# USB3SS0 register map
Vendor: Texas Instruments
Peripheral module from a debugger description file (folder am65x).
Registers are 32-bit, access not given, reset values left out (the file's numbers can be read two ways) unless marked. A register's access mark holds for its fields unless they carry their own. Offsets are as the file gives them; lines under a group give offsets from that group; [hi:lo] are bit positions; {n}, {i} and the like mark numbered series; 'fields as' and 'values as' point back to an identical list; <NAME> marks a mode.

## USB3SS0
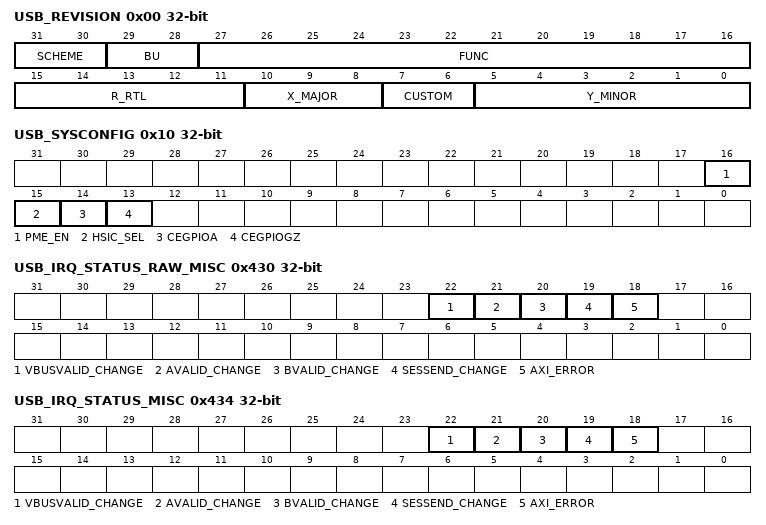
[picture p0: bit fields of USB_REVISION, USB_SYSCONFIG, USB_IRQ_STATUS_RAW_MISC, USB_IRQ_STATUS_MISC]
0x00 USB_REVISION ro — IP Revision Identifier (X.Y.R) Used by software to track features, bugs, and compatibility
  [31:30] SCHEME
  [29:28] BU
  [27:16] FUNC — Module ID
  [15:11] R_RTL — RTL version
  [10:8] X_MAJOR — Major version
  [7:6] CUSTOM — Custom version
  [5:0] Y_MINOR — Minor version
0x10 USB_SYSCONFIG access per field — Controls various parameters of the master and slave interfaces.
  [16] PME_EN rw — Enable signal for the pme_generation. When the Run/Stop bit of the USB Command Register is cleared during USB suspend mode, the core cannot generate event and cannot assert regular interrupt. In this case, the core asserts pme_generation signal to report any wakeup condition if PME_EN is high.
  [15] HSIC_SEL rw — Select USB2PHY when 0, HSIC when 1
  [14] CEGPIOA rw — GPO mode data for CE.
  [13] CEGPIOGZ rw — CE GPO output buffer control.
0x20 USB_IRQ_STATUS_RAW_MAIN_i — The IRQ_STATUS_RAW_MAIN_i register allows the usbss interrupt sources to be manually set when writing a 1 to a specific bit. Parameter i ranges from 0 to 15. Offset = 20h + (i * 10h), where: i = 0h to Fh
  [0] IRQ_STATUS_RAW_MAIN — Write 0: No action Write 1: Set event Read 0: No event pending Read 1: Event pending (access RW1S)
0x24 USB_IRQ_STATUS_MAIN_i — The IRQ_STATUS_MAIN_i register allows the usbss interrupt sources to be manually cleared when writing a 1 to a specific bit. Parameter i ranges from 0 to 15. Offset = 24h + (i * 10h), where: i = 0h to Fh
  [0] IRQ_STATUS_MAIN — Write 0: No action Write 1: Clear event Read 0: No event pending Read 1: Event pending (access RW1C)
0x42C USB_IRQ_EOI_MISC — The End of Interrupt (EOI) MISC Register allows the CPU to acknowledge completion of an interrupt by writing to the EOI for MISC interrupt sources. An eoi_write signal will be generated and another interrupt will be triggered if interrupt sources remain. This register will be reset one cycle after it has been written to. The EOI register is used to re-trigger the pulse interrupt signal to ensure that any nested interrupt events are serviced. The software interrupt handler must write to the EOI register at the end of the current interrupt processing routine, so that new events can re-trigger the pulse interrupt signal again. For level interrupt signals the EOI register is not functional and must not be used.
  [0] EOI_MISC — Write 1 to flag End Of Interrupt 'MISC' (access RW1S)
0x430 USB_IRQ_STATUS_RAW_MISC — The register allows the usbss interrupt sources to be manually set when writing a 1 to a specific bit. Write 0: No action Write 1: Set event Read 0: No event pending Read 1: Event pending
  [22] VBUSVALID_CHANGE — Set when VBUSVALID changes state (access RW1S)
  [21] AVALID_CHANGE — Set when AVALID changes state (access RW1S)
  [20] BVALID_CHANGE — Set when BVALID changes state (access RW1S)
  [19] SESSEND_CHANGE — Set when SESSEND changes state (access RW1S)
  [18] AXI_ERROR — Set by host_system_err when HW detects an error response to AXI master. USB_USBCMD[3] HSEE must be set in the controller. Error reflected in the controller USB_USBSTS[2] HSE field. (access RW1S)
0x434 USB_IRQ_STATUS_MISC — The register allows the usbss interrupt sources to be manually cleared when writing a 1 to a specific bit. Write 0: No action Write 1: Clear event Read 0: No event pending Read 1: Event pending
  [22] VBUSVALID_CHANGE — Set when VBUSVALID changes state (access RW1C)
  [21] AVALID_CHANGE — Set when AVALID changes state (access RW1C)
  [20] BVALID_CHANGE — Set when BVALID changes state (access RW1C)
  [19] SESSEND_CHANGE — Set when SESSEND changes state (access RW1C)
  [18] AXI_ERROR — Set by host_system_err when HW detects an error response to AXI master. USB_USBCMD[3] HSEE must be set in the controller. Error reflected in the controller USB_USBSTS[2] HSE field. (access RW1C)
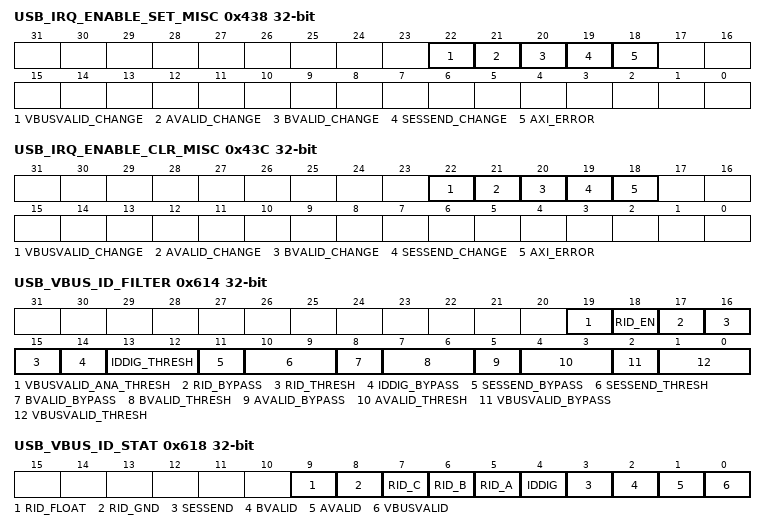
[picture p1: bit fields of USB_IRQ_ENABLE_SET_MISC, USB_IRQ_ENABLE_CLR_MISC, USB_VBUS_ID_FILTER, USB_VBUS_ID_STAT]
0x438 USB_IRQ_ENABLE_SET_MISC — The register allows the usbss interrupt sources to be manually enabled when writing a 1 to a specific bit. Write 0: No action Write 1: Enable event Read 0: Event is disabled Read 1: Event is enabled
  [22] VBUSVALID_CHANGE — Event enable set (access RW1S)
  [21] AVALID_CHANGE — Event enable set (access RW1S)
  [20] BVALID_CHANGE — Event enable set (access RW1S)
  [19] SESSEND_CHANGE — Event enable set (access RW1S)
  [18] AXI_ERROR — Event enable set (access RW1S)
0x43C USB_IRQ_ENABLE_CLR_MISC — The register allows the usbss interrupt sources to be manually disabled when writing a 1 to a specific bit. Write 0: No action Write 1: Disable event Read 0: Event is disabled Read 1: Event is enabled
  [22] VBUSVALID_CHANGE — Event enable clear (access RW1C)
  [21] AVALID_CHANGE — Event enable clear (access RW1C)
  [20] BVALID_CHANGE — Event enable clear (access RW1C)
  [19] SESSEND_CHANGE — Event enable clear (access RW1C)
  [18] AXI_ERROR — Event enable clear (access RW1C)
0x450 USB_IRQ_STATUS_RAW_OTG — The Register allows the OTG interrupt source to be manually triggered when writing a 1 to a specific bit. A read of this register returns the interrupt event pending value. General actions per bit: Write 0: No action Write 1: Set event Read 0: No event pending Read 1: Event pending
  [0] OTG_EVNT — Interrupt raw status for OTG event (access RW1S)
0x454 USB_IRQ_STATUS_OTG — The Register allows the OTG source to be manually cleared when writing a 1 to a specific bit. A read of this register returns the interrupt event pending value. General actions per bit: Write 0: No action Write 1: Clear event Read 0: No event pending Read 1: Event pending
  [0] OTG_EVNT — Interrupt status for OTG event (access RW1C)
0x460 USB_IRQ_STATUS_RAW_ADP — The Register allows the ADP interrupt source to be manually triggered when writing a 1 to a specific bit. A read of this register returns the interrupt event pending value. General actions per bit: Write 0: No action Write 1: Set event Read 0: No event pending Read 1: Event pending
  [0] ADP_EVNT — Interrupt raw status for ADP event (access RW1S)
0x464 USB_IRQ_STATUS_ADP — The Register allows the ADP source to be manually cleared when writing a 1 to a specific bit. A read of this register returns the interrupt event pending value. General actions per bit: Write 0: No action Write 1: Clear event Read 0: No event pending Read 1: Event pending
  [0] ADP_EVNT — Interrupt status for ADP event (access RW1C)
0x470 USB_IRQ_STATUS_RAW_BC — The Register allows the BC interrupt source to be manually triggered when writing a 1 to a specific bit. A read of this register returns the interrupt event pending value. General actions per bit: Write 0: No action Write 1: Set event Read 0: No event pending Read 1: Event pending
  [0] BC_EVNT — Interrupt raw status for BC event (access RW1S)
0x474 USB_IRQ_STATUS_BC — The Register allows the BC source to be manually cleared when writing a 1 to a specific bit. A read of this register returns the interrupt event pending value. General actions per bit: Write 0: No action Write 1: Clear event Read 0: No event pending Read 1: Event pending
  [0] BC_EVNT — Interrupt status for BC event (access RW1C)
0x480 USB_IRQ_STATUS_RAW_PME_GEN — The Register allows the PME_GEN interrupt source to be manually triggered when writing a 1 to a specific bit. A read of this register returns the interrupt event pending value. General actions per bit: Write 0: No action Write 1: Set event Read 0: No event pending Read 1: Event pending
  [0] PME_GEN_EVNT — Interrupt raw status for PME_GEN event (access RW1S)
0x484 USB_IRQ_STATUS_PME_GEN — The Register allows the PME_GEN source to be manually cleared when writing a 1 to a specific bit. A read of this register returns the interrupt event pending value. General actions per bit: Write 0: No action Write 1: Clear event Read 0: No event pending Read 1: Event pending
  [0] PME_GEN_EVNT — Interrupt status for PME_GEN event (access RW1C)
0x614 USB_VBUS_ID_FILTER access per field — The vbus and id comparator signals may be filtered by controlling these register values.
  [19] VBUSVALID_ANA_THRESH rw — Set threshold for VBUSVALID. Drives VALID_THRESHOLD_SEL on the USB_VBUS_IDD
  [18] RID_EN rw — Enable RID detection when =1
  [17] RID_BYPASS rw — 0= use filter, 1= bypass filter
  [16:15] RID_THRESH rw — 00= 1us, 01= 100us, 10= 5ms, 11= 50ms. UTMI_CLK latency for RID_FLOAT, RID_GND, RID_A, RID_B and RID_C
  [14] IDDIG_BYPASS rw — 0= use filter, 1= bypass filter for IDDIG
  [13:12] IDDIG_THRESH rw — 00= 1us, 01= 100us, 10= 5ms, 11= 50ms. UTMI_CLK latency for IDDIG
  [11] SESSEND_BYPASS rw — 0= use filter, 1= bypass filter for SESSEND
  [10:9] SESSEND_THRESH rw — 00= 1us, 01= 100us, 10= 5ms, 11= 50ms. UTMI_CLK latency for SESSEND
  [8] BVALID_BYPASS rw — 0= use filter, 1= bypass filter
  [7:6] BVALID_THRESH rw — 00= 1us, 01= 100us, 10= 5ms, 11= 50ms. UTMI_CLK latency for BVALID
  [5] AVALID_BYPASS rw — 0= use filter, 1= bypass filter for AVALID
  [4:3] AVALID_THRESH rw — 00= 1us, 01= 100us, 10= 5ms, 11= 50ms. UTMI_CLK latency for AVALID
  [2] VBUSVALID_BYPASS rw — 0= use filter, 1= bypass filter for VBUSVALID
  [1:0] VBUSVALID_THRESH rw — 00= 1us, 01= 100us, 10= 5ms, 11= 50ms. UTMI_CLK latency for VBUSVALID
0x618 USB_VBUS_ID_STAT ro — Status bits of VBUS and ID detected signals after filter.
  [9] RID_FLOAT — Filtered RID_FLOAT
  [8] RID_GND — Filtered RID_GND
  [7] RID_C — Filtered RID_C
  [6] RID_B — Filtered RID_B
  [5] RID_A — Filtered RID_A
  [4] IDDIG — Filtered IDDIG
  [3] SESSEND — Filtered SESSEND
  [2] BVALID — Filtered BVALID
  [1] AVALID — Filtered AVALID
  [0] VBUSVALID — Filtered VBUSVALID
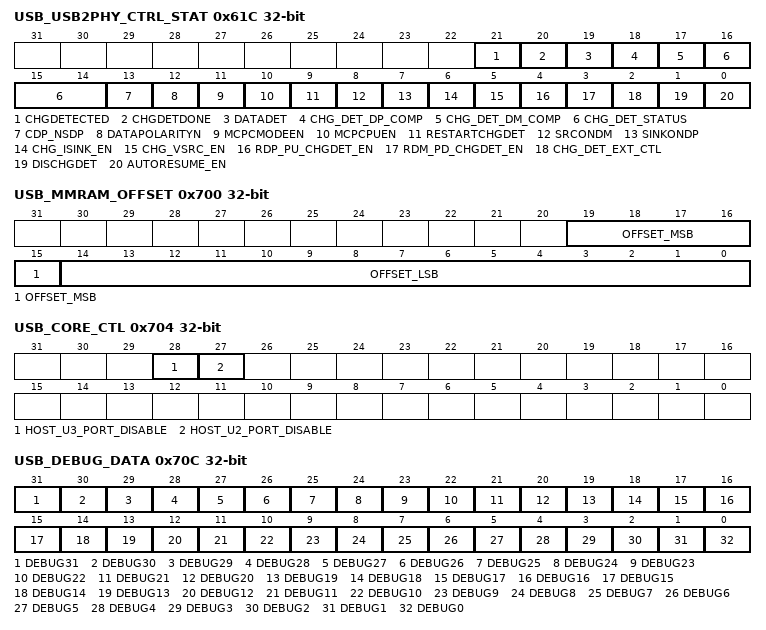
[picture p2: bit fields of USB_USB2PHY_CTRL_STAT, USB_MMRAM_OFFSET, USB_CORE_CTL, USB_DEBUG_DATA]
0x61C USB_USB2PHY_CTRL_STAT access per field — The USB2PHY ports with corresponding names arecontrolled by these registers. Status bits correspond to the USB2PHY outputs of the same name.
  [21] CHGDETECTED ro — Corresponds to USB2PHY port CHGDETECTED
  [20] CHGDETDONE ro — Corresponds to USB2PHY port CHGDETDONE
  [19] DATADET ro — Corresponds to USB2PHY port DATADET
  [18] CHG_DET_DP_COMP ro — Corresponds to USB2PHY port CHG_DET_DP_COMP
  [17] CHG_DET_DM_COMP ro — Corresponds to USB2PHY port CHG_DET_DM_COMP
  [16:14] CHG_DET_STATUS ro — Corresponds to USB2PHY port CHG_DET_STATUS
  [13] CDP_NSDP rw — Allows for charging downstream port control =1
  [12] DATAPOLARITYN rw — Corresponds to USB2PHY port DATAPOLARITYN
  [11] MCPCMODEEN rw — Corresponds to USB2PHY port MCPCMODEEN
  [10] MCPCPUEN rw — Corresponds to USB2PHY port MCPCPUEN
  [9] RESTARTCHGDET rw — Corresponds to USB2PHY port RESTARTCHGDET
  [8] SRCONDM rw — Corresponds to USB2PHY port SRCONDM
  [7] SINKONDP rw — Corresponds to USB2PHY port SINKONDP
  [6] CHG_ISINK_EN rw — Corresponds to USB2PHY port CHG_ISINK_EN
  [5] CHG_VSRC_EN rw — Corresponds to USB2PHY port CHG_VSRC_EN
  [4] RDP_PU_CHGDET_EN rw — Corresponds to USB2PHY port RDP_PU_CHGDET_EN
  [3] RDM_PD_CHGDET_EN rw — Corresponds to USB2PHY port RDM_PD_CHGDET_EN
  [2] CHG_DET_EXT_CTL rw — Corresponds to USB2PHY port CHG_DET_EXT_CTL
  [1] DISCHGDET rw — Corresponds to USB2PHY port DISCHGDET
  [0] AUTORESUME_EN rw — Corresponds to USB2PHY port AUTORESUME_EN
0x700 USB_MMRAM_OFFSET access per field — Offset of Memory-mapped RAM accesses. Page is remapped from 0x8000 to 0xFFFF (32 kbyte)
  [19:15] OFFSET_MSB rw — Byte offset MSBits = page offset
  [14:0] OFFSET_LSB ro — Byte offset LSBits, always 0
0x704 USB_CORE_CTL access per field — XHCI rev, port disable pseudo-static parameters
  [28] HOST_U3_PORT_DISABLE rw — USB3 port disable, overriding xHCI driver
  [27] HOST_U2_PORT_DISABLE rw — USB2 port disable, overriding xHCI driver
0x708 USB_DEBUG_CFG access per field — Configuration of debug data for observation and for control. 0x0 = debug outputs are tied low 0x1 = debug outputs are UTMI interface signals 0x2 = debug outputs are PIPE3 interface signals 0x3 = debug outputs are xHC internal signals 0x4 = debug outputs are controller logic_analyzer_trace[31:0] 0x5 = debug outputs are controller logic_analyzer_trace[63:32]
  [2:0] SEL_DBG rw — Selects observed local signals
0x70C USB_DEBUG_DATA ro — Data that is observable Observable data is selected via .sel_dbg , shown only for sel_dbg = (1,2,3)
  [31] DEBUG31 — sel= 1: utmi_sessend sel= 2: pipe_rxstatus[2] sel= 3: core_sm2bl_cur_mode
  [30] DEBUG30 — sel= 1: utmi_vbusvalid sel= 2: pipe_rxstatus[1] sel= 3: core_suspend_n
  [29] DEBUG29 — sel= 1: utmi_bvalid sel= 2: pipe_rxstatus[0] sel= 3: core_suspend_com_n
  [28] DEBUG28 — sel= 1: utmi_avalid sel= 2: pipe_elecidle sel= 3: core_u2_dssr_state[3]
  [27] DEBUG27 — sel= 1: utmi_iddig sel= 2: pipe_phystatus sel= 3: core_u2_dssr_state[2]
  [26] DEBUG26 — sel= 1: utmi_hostdisconnect sel= 2: pipe_rxvalid sel= 3: core_u2_dssr_state[1]
  [25] DEBUG25 — sel= 1: utmi_txbitstuffenableh sel= 2: pipe_rxdatak[3] sel= 3: core_u2_dssr_state[0]
  [24] DEBUG24 — sel= 1: utmi_txbitstuffenable sel= 2: pipe_rxdatak[2] sel= 3: core_u2mac_txrx_state_1[4]
  [23] DEBUG23 — sel= 1: utmi_dischrgvbus sel= 2: pipe_rxdatak[1] sel= 3: core_u2mac_txrx_state_1[3]
  [22] DEBUG22 — sel= 1: utmi_chrgvbus sel= 2: pipe_rxdatak[0] sel= 3: core_u2mac_txrx_state_1[2]
  [21] DEBUG21 — sel= 1: utmi_drvvbus sel= 2: pipe_rxpclk sel= 3: core_u2mac_txrx_state_1[1]
  [20] DEBUG20 — sel= 1: utmi_dmpulldown sel= 2: pipe_rxtermination sel= 3: core_u2mac_txrx_state_1[0]
  [19] DEBUG19 — sel= 1: utmi_dppulldown sel= 2: pipe_txswing sel= 3: core_u2mac_txrx_state_0[4]
  [18] DEBUG18 — sel= 1: utmi_idpullup sel= 2: pipe_txmargin[2] sel= 3: core_u2mac_txrx_state_0[3]
  [17] DEBUG17 — sel= 1: utmi_linestate[1] sel= 2: pipe_txmargin[1] sel= 3: core_u2mac_txrx_state_0[2]
  [16] DEBUG16 — sel= 1: utmi_linestate[0] sel= 2: pipe_txmargin[0] sel= 3: core_u2mac_txrx_state_0[1]
  [15] DEBUG15 — sel= 1: utmi_opmode[1] sel= 2: pipe_txdeemph[1] sel= 3: core_u2mac_txrx_state_0[0]
  [14] DEBUG14 — sel= 1: utmi_opmode[0] sel= 2: pipe_txdeemph[0] sel= 3: core_u2_prt_state[4]
  [13] DEBUG13 — sel= 1: utmi_termselect sel= 2: pipe_powerdown[1] sel= 3: core_u2_prt_state[3]
  [12] DEBUG12 — sel= 1: utmi_xcvrselect[1] sel= 2: pipe_powerdown[0] sel= 3: core_u2_prt_state[2]
  [11] DEBUG11 — sel= 1: utmi_xcvrselect[0] sel= 2: pipe_reset_n sel= 3: core_u2_prt_state[1]
  [10] DEBUG10 — sel= 1: utmi_suspendm sel= 2: pipe_rxeqtraining sel= 3: core_u2_prt_state[0]
  [9] DEBUG9 — sel= 1: utmi_reset sel= 2: pipe_rxpolarity sel= 3: core_gsts_buserraddvld
  [8] DEBUG8 — sel= 1: utmi_rxerror sel= 2: pipe_txoneszeros sel= 3: debug_mclk_usof_number[0]
  [7] DEBUG7 — sel= 1: utmi_rxvalidh sel= 2: pipe_txelecidle sel= 3: core_ltdb_link_state[3]
  [6] DEBUG6 — sel= 1: utmi_rxvalid sel= 2: pipe_txdetectrxloopback sel= 3: core_ltdb_link_state[2]
  [5] DEBUG5 — sel= 1: utmi_rxactive sel= 2: pipe_elasticitybuffermode sel= 3: core_ltdb_link_state[1]
  [4] DEBUG4 — sel= 1: utmi_txready sel= 2: pipe_txdatak[3] sel= 3: core_ltdb_link_state[0]
  [3] DEBUG3 — sel= 1: utmi_txdatah sel= 2: pipe_txdatak[2] sel= 3: core_ltdb_substate[3]
  [2] DEBUG2 — sel= 1: utmi_txdata sel= 2: pipe_txdatak[1] sel= 3: core_ltdb_substate[2]
  [1] DEBUG1 — sel= 1: utmi_databus16_8 or wordinterface sel= 2: pipe_txdatak[0] sel= 3: core_ltdb_substate[1]
  [0] DEBUG0 — sel= 1: utmi_clk sel= 2: pipe_txpclk sel= 3: core_ltdb_substate[0]
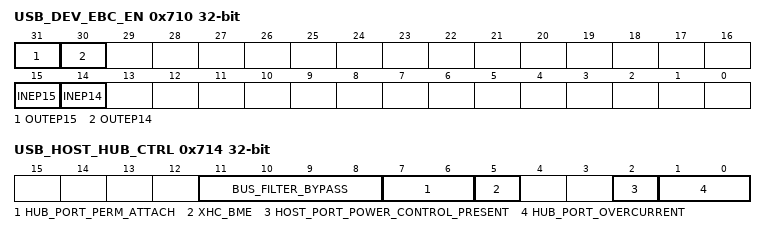
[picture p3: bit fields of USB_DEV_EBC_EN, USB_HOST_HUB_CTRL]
0x710 USB_DEV_EBC_EN access per field — Enable External Buffer Control (EBC) for selected endpoints. Device mode only. INEP[x] Enable EBC HW throttling for IN EP (USB transmit). To enable logical EP IN #i, set [x]. In DEPCFG command for this EP, DEPCMDPAR1[x] = LimitOutstandingTxDMA should then also be set to 1 OUTEP[x] Enable EBC HW throttling for OUT EP, per bit (USB receive). To enable logical OUT EP #i, set [x+16] In DEPCFG command for this EP, DEPCMDPAR1[x] = LimitOutstandingTxDMA should then also be set to 1 x equals 15
  [31] OUTEP15 rw — ENABLE EBC HW throttling (USB receive) for OUT EP 15
  [30] OUTEP14 rw — ENABLE EBC HW throttling (USB receive) for OUT EP 14
  [15] INEP15 rw — ENABLE EBC HW throttling (USB transmit) for IN EP 15
  [14] INEP14 rw — ENABLE EBC HW throttling (USB transmit) for IN EP 14
0x714 USB_HOST_HUB_CTRL access per field — The Register is a collection of various input signals that control the xHC controllers Host or Hub interfaces. These signals are used regardless if a Host or Hub is implemented or not.
  [11:8] BUS_FILTER_BYPASS rw — Bus Filter Bypass bit [0]: bypass the filter for vbusvalid bit [1]: bypass the filter for pipe3_PowerPresent bit [2]: bypass the filter for avalid, bvalid, and sessend bit [3]: bypass the filter for iddig 0 = filter enabled 1 = filter disabled
  [7:6] HUB_PORT_PERM_ATTACH rw — Indicates if the device attached to a downstream port is permanently attached or not. Bit 6 is the USB2 port and bit 7 is the SS port. 0 - Not permanently attached 1 - Permanently attached
  [5] XHC_BME rw — This signal is used to disable the bus mastering capability of the xHC. In a PCI system, it comes from the Bus Master Enable (BME) bit of the Device Control Register in the PCI Configuration register space. 1'b 0: Bus mastering capability is disabled. The host controller cannot use the bus master interface. 1'b 1: Bus mastering capability is enabled.
  [2] HOST_PORT_POWER_CONTROL_PRESENT rw — This port defines the bit [3] of Capability Parameters (HCCPARAMS). Change the PPC value through the pin Port Power Control (PPC). This indicates whether the host controller implementation includes port power control. 0 - Indicates that the port does not have port power switches. 1 - Indicates that the port has port power switches.
  [1:0] HUB_PORT_OVERCURRENT rw — This is the per port Overcurrent indication of the root-hub ports. Bit 0 is the USB2 port and bit 1 is the SS port. 0 - No Overcurrent 1 - Overcurrent
